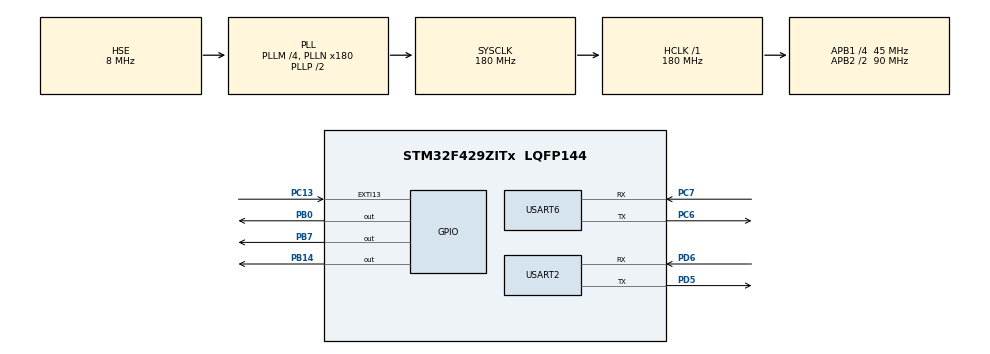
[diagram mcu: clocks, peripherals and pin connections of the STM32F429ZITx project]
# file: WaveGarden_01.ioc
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Dma.Request0=USART2_RX
Dma.Request1=USART6_RX
Dma.USART2_RX.0.Direction=DMA_PERIPH_TO_MEMORY
Dma.USART2_RX.0.FIFOMode=DMA_FIFOMODE_DISABLE
Dma.USART2_RX.0.Instance=DMA1_Stream5
Dma.USART2_RX.0.MemDataAlignment=DMA_MDATAALIGN_BYTE
Dma.USART2_RX.0.MemInc=DMA_MINC_ENABLE
Dma.USART2_RX.0.Mode=DMA_NORMAL
Dma.USART2_RX.0.PeriphDataAlignment=DMA_PDATAALIGN_BYTE
Dma.USART2_RX.0.PeriphInc=DMA_PINC_DISABLE
Dma.USART2_RX.0.Priority=DMA_PRIORITY_LOW
Dma.USART6_RX.1.Direction=DMA_PERIPH_TO_MEMORY
Dma.USART6_RX.1.FIFOMode=DMA_FIFOMODE_DISABLE
Dma.USART6_RX.1.Instance=DMA2_Stream1
Dma.USART6_RX.1.MemDataAlignment=DMA_MDATAALIGN_BYTE
Dma.USART6_RX.1.MemInc=DMA_MINC_ENABLE
Dma.USART6_RX.1.Mode=DMA_NORMAL
Dma.USART6_RX.1.PeriphDataAlignment=DMA_PDATAALIGN_BYTE
Dma.USART6_RX.1.PeriphInc=DMA_PINC_DISABLE
Dma.USART6_RX.1.Priority=DMA_PRIORITY_LOW
Mcu.Family=STM32F4
Mcu.Name=STM32F429ZITx
Mcu.Package=LQFP144
NVIC.DMA1_Stream5_IRQn=true\:0\:0\:false\:false\:true\:false\:true\:true
NVIC.DMA2_Stream1_IRQn=true\:0\:0\:false\:false\:true\:false\:true\:true
NVIC.EXTI15_10_IRQn=true\:0\:0\:false\:false\:true\:true\:true\:true
NVIC.PriorityGroup=NVIC_PRIORITYGROUP_4
NVIC.TIM1_UP_TIM10_IRQn=true\:0\:0\:false\:false\:true\:true\:true\:true
NVIC.USART2_IRQn=true\:0\:0\:false\:false\:true\:true\:true\:true
NVIC.USART6_IRQn=true\:0\:0\:false\:false\:true\:true\:true\:true
PA13.Mode=Serial_Wire
PA13.Signal=SYS_JTMS-SWDIO
PA14.Mode=Serial_Wire
PA14.Signal=SYS_JTCK-SWCLK
PB0.Signal=GPIO_Output
PB14.Signal=GPIO_Output
PB7.Signal=GPIO_Output
PC13.Signal=GPXTI13
PC6.Mode=Asynchronous
PC6.Signal=USART6_TX
PC7.Mode=Asynchronous
PC7.Signal=USART6_RX
PD5.Mode=Asynchronous
PD5.Signal=USART2_TX
PD6.Mode=Asynchronous
PD6.Signal=USART2_RX
PH0/OSC_IN.Mode=HSE-External-Clock-Source
PH0/OSC_IN.Signal=RCC_OSC_IN
PH1/OSC_OUT.Mode=HSE-External-Clock-Source
PH1/OSC_OUT.Signal=RCC_OSC_OUT
ProjectManager.HeapSize=0x200
ProjectManager.StackSize=0x400
ProjectManager.TargetToolchain=STM32CubeIDE
RCC.48MHZClocksFreq_Value=90000000
RCC.AHBFreq_Value=180000000
RCC.APB1CLKDivider=RCC_HCLK_DIV4
RCC.APB1Freq_Value=45000000
RCC.APB1TimFreq_Value=90000000
RCC.APB2CLKDivider=RCC_HCLK_DIV2
RCC.APB2Freq_Value=90000000
RCC.APB2TimFreq_Value=180000000
RCC.CortexFreq_Value=180000000
RCC.HCLKFreq_Value=180000000
RCC.HSE_VALUE=8000000
RCC.HSI_VALUE=16000000
RCC.LSE_VALUE=32768
RCC.PLLM=4
RCC.PLLN=180
RCC.PLLSourceVirtual=RCC_PLLSOURCE_HSE
RCC.SYSCLKFreq_VALUE=180000000
RCC.SYSCLKSource=RCC_SYSCLKSOURCE_PLLCLK
RCC.VCOOutputFreq_Value=360000000
TIM1.Period=1000-1
TIM1.Prescaler=180-1
USART2.VirtualMode=VM_ASYNC
USART6.VirtualMode=VM_ASYNC
VP_TIM1_VS_ClockSourceINT.Mode=Internal
board=custom

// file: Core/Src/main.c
/* USER CODE BEGIN Header */
/**
  ******************************************************************************
  * @file           : main.c
  * @brief          : Main program body
  ******************************************************************************
  * @attention
  *
  * Copyright (c) 2025 STMicroelectronics.
  * All rights reserved.
  *
  * This software is licensed under terms that can be found in the LICENSE file
  * in the root directory of this software component.
  * If no LICENSE file comes with this software, it is provided AS-IS.
  *
  ******************************************************************************
  */
/* USER CODE END Header */
#include "main.h"
#include "dma.h"
#include "tim.h"
#include "usart.h"
#include "gpio.h"

void SystemClock_Config(void);

int main(void)
{

  /* MCU Configuration--------------------------------------------------------*/

  /* Reset of all peripherals, Initializes the Flash interface and the Systick. */
  HAL_Init();

  /* Configure the system clock */
  SystemClock_Config();

  /* Initialize all configured peripherals */
  MX_GPIO_Init();
  MX_DMA_Init();
  MX_USART2_UART_Init();
  MX_TIM1_Init();
  MX_USART6_UART_Init();
  /* USER CODE BEGIN 2 */
  print_boot_message();
  HAL_TIM_Base_Start_IT(&htim1);

  // HAL_UART_Receive_DMA(&huart2, uart2_rx_buf, UART2_RX_BUF_SIZE);
  // __HAL_UART_ENABLE_IT(&huart2, UART_IT_IDLE);  // IDLE ?��?��?��?�� ?��?��?��
  HAL_UARTEx_ReceiveToIdle_DMA(&huart2, (uint8_t *) uart2_rx_buf, UART2_RX_BUF_SIZE);
  __HAL_DMA_DISABLE_IT(&hdma_usart2_rx, DMA_IT_HT);

  HAL_UARTEx_ReceiveToIdle_DMA(&huart6, (uint8_t *) uart6_rx_buf, UART6_RX_BUF_SIZE);
  __HAL_DMA_DISABLE_IT(&hdma_usart6_rx, DMA_IT_HT);
  /* USER CODE END 2 */

  /* Infinite loop */
  /* USER CODE BEGIN WHILE */
  while (1)
  {
    LED_Task();
    UART2_Process();
    UART6_Process();
    /* USER CODE END WHILE */

  }
}

void SystemClock_Config(void)
{
  RCC_OscInitTypeDef RCC_OscInitStruct = {0};
  RCC_ClkInitTypeDef RCC_ClkInitStruct = {0};

  /** Configure the main internal regulator output voltage
  */
  __HAL_RCC_PWR_CLK_ENABLE();
  __HAL_PWR_VOLTAGESCALING_CONFIG(PWR_REGULATOR_VOLTAGE_SCALE1);

  /** Initializes the RCC Oscillators according to the specified parameters
  * in the RCC_OscInitTypeDef structure.
  */
  RCC_OscInitStruct.OscillatorType = RCC_OSCILLATORTYPE_HSE;
  RCC_OscInitStruct.HSEState = RCC_HSE_BYPASS;
  RCC_OscInitStruct.PLL.PLLState = RCC_PLL_ON;
  RCC_OscInitStruct.PLL.PLLSource = RCC_PLLSOURCE_HSE;
  RCC_OscInitStruct.PLL.PLLM = 4;
  RCC_OscInitStruct.PLL.PLLN = 180;
  RCC_OscInitStruct.PLL.PLLP = RCC_PLLP_DIV2;
  RCC_OscInitStruct.PLL.PLLQ = 4;
  if (HAL_RCC_OscConfig(&RCC_OscInitStruct) != HAL_OK)
  {
    Error_Handler();
  }

  /** Activate the Over-Drive mode
  */
  if (HAL_PWREx_EnableOverDrive() != HAL_OK)
  {
    Error_Handler();
  }

  /** Initializes the CPU, AHB and APB buses clocks
  */
  RCC_ClkInitStruct.ClockType = RCC_CLOCKTYPE_HCLK|RCC_CLOCKTYPE_SYSCLK
                              |RCC_CLOCKTYPE_PCLK1|RCC_CLOCKTYPE_PCLK2;
  RCC_ClkInitStruct.SYSCLKSource = RCC_SYSCLKSOURCE_PLLCLK;
  RCC_ClkInitStruct.AHBCLKDivider = RCC_SYSCLK_DIV1;
  RCC_ClkInitStruct.APB1CLKDivider = RCC_HCLK_DIV4;
  RCC_ClkInitStruct.APB2CLKDivider = RCC_HCLK_DIV2;

  if (HAL_RCC_ClockConfig(&RCC_ClkInitStruct, FLASH_LATENCY_5) != HAL_OK)
  {
    Error_Handler();
  }
}

void Error_Handler(void)
{
  __disable_irq();
  while (1)
  {
  }
}
